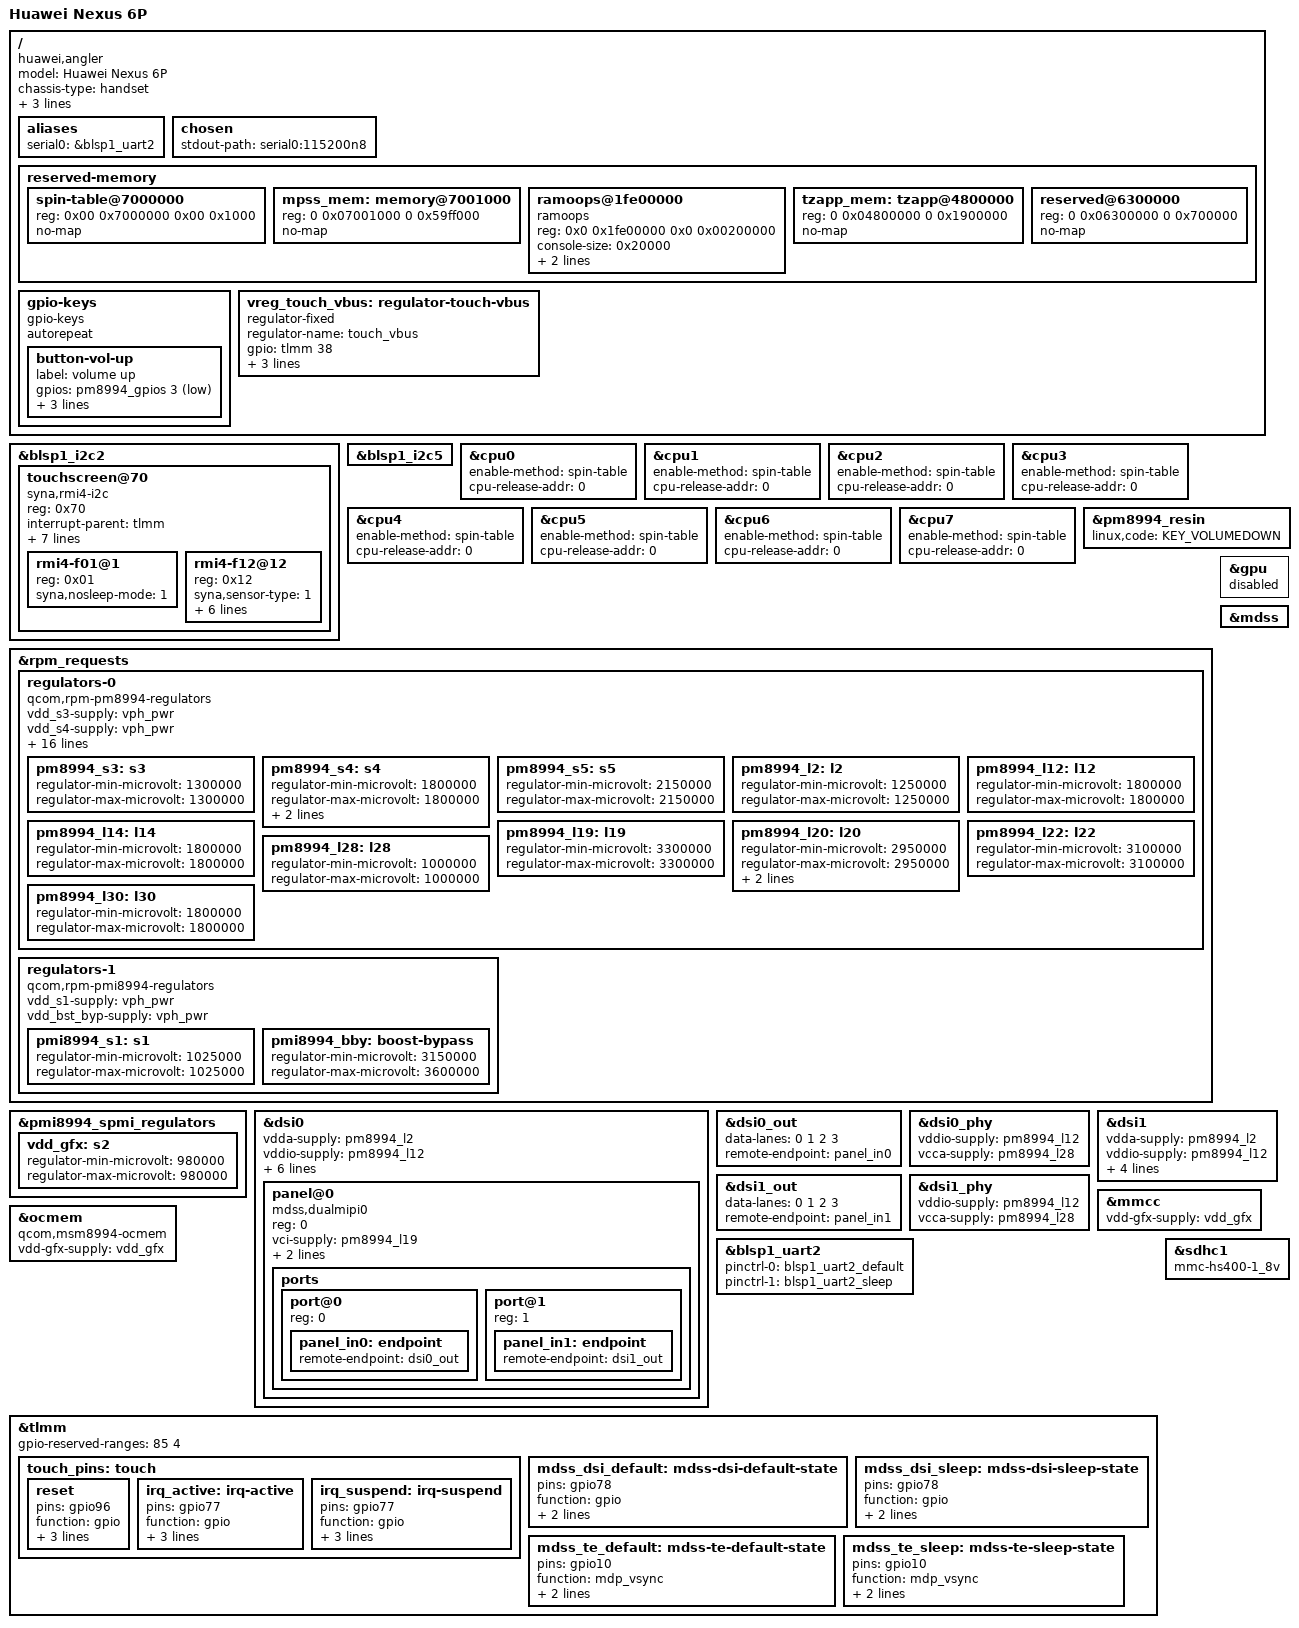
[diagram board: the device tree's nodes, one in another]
// SPDX-License-Identifier: GPL-2.0-only
/*
 * Copyright (c) 2015, Huawei Inc. All rights reserved.
 * Copyright (c) 2016, The Linux Foundation. All rights reserved.
 * Copyright (c) 2021-2024, Petr Vorel <petr.vorel@gmail.com>
 */

/dts-v1/;

#include "msm8994.dtsi"
#include "pm8994.dtsi"
#include "pmi8994.dtsi"
#include <dt-bindings/leds/common.h>

/* disabled downstream */
/delete-node/ &dfps_data_mem;

/* interferes with spin tables */
/delete-node/ &mpss_mem;

/* Framebuffer is somewhere else */
/delete-node/ &cont_splash_mem;

/ {
	model = "Huawei Nexus 6P";
	compatible = "huawei,angler", "qcom,msm8994";
	chassis-type = "handset";
	/* required for bootloader to select correct board */
	qcom,msm-id = <207 0x20000>;
	qcom,pmic-id = <0x10009 0x1000a 0x0 0x0>;
	qcom,board-id = <8026 0>;

	aliases {
		serial0 = &blsp1_uart2;
	};

	chosen {
		stdout-path = "serial0:115200n8";
	};

	reserved-memory {
		#address-cells = <2>;
		#size-cells = <2>;
		ranges;

		spin-table@7000000 {
			reg = <0x00 0x7000000 0x00 0x1000>;
			no-map;
		};

		mpss_mem: memory@7001000 {
			reg = <0 0x07001000 0 0x59ff000>;
			no-map;
		};
	
		ramoops@1fe00000 {
			compatible = "ramoops";
			reg = <0x0 0x1fe00000 0x0 0x00200000>;
			console-size = <0x20000>;
			pmsg-size = <0x20000>;
			record-size = <0x10000>;
		};

		tzapp_mem: tzapp@4800000 {
			reg = <0 0x04800000 0 0x1900000>;
			no-map;
		};

		reserved@6300000 {
			reg = <0 0x06300000 0 0x700000>;
			no-map;
		};
	};

	gpio-keys {
		compatible = "gpio-keys";
		autorepeat;

		button-vol-up {
			label = "volume up";
			gpios = <&pm8994_gpios 3 GPIO_ACTIVE_LOW>;
			linux,code = <KEY_VOLUMEUP>;
			wakeup-source;
			debounce-interval = <15>;
		};
	};

	vreg_touch_vbus: regulator-touch-vbus {
		compatible = "regulator-fixed";
		regulator-name = "touch_vbus";
		gpio = <&tlmm 38 GPIO_ACTIVE_HIGH>;
		enable-active-high;
		regulator-always-on;
		regulator-boot-on;
	};
};

&blsp1_i2c2 {
  status = "okay";

  touchscreen@70 {
    compatible = "syna,rmi4-i2c";
    reg = <0x70>;
    #address-cells = <1>;
    #size-cells = <0>;

    interrupt-parent = <&tlmm>;
    interrupts = <77 IRQ_TYPE_EDGE_FALLING>;

    vdd-supply = <&pm8994_l22>;
    vio-supply = <&pm8994_l30>;

    reset-gpios = <&tlmm 96 GPIO_ACTIVE_LOW>;

    syna,startup-delay-ms = <200>;

    pinctrl-names = "default", "sleep";
    pinctrl-0 = <&irq_active>;
    pinctrl-1 = <&irq_suspend>;

    rmi4-f01@1 {
      reg = <0x01>;
      syna,nosleep-mode = <1>;
    };

    rmi4-f12@12 {
      reg = <0x12>;
      syna,sensor-type = <1>;
      syna,clip-x-low = <0>;
      syna,clip-x-high = <1439>;
      syna,clip-y-low = <0>;
      syna,clip-y-high = <2559>;
      syna,x-flip = <1>;
      syna,y-flip = <1>;
    };
  };
};


&blsp1_i2c5 {
	status = "okay";

	/* SMB1351 charger */
};


&cpu0 {
	enable-method = "spin-table";
	cpu-release-addr = /bits/ 64 <0>;
};

&cpu1 {
	enable-method = "spin-table";
	cpu-release-addr = /bits/ 64 <0>;
};

&cpu2 {
	enable-method = "spin-table";
	cpu-release-addr = /bits/ 64 <0>;
};

&cpu3 {
	enable-method = "spin-table";
	cpu-release-addr = /bits/ 64 <0>;
};

&cpu4 {
	enable-method = "spin-table";
	cpu-release-addr = /bits/ 64 <0>;
};

&cpu5 {
	enable-method = "spin-table";
	cpu-release-addr = /bits/ 64 <0>;
};

&cpu6 {
	enable-method = "spin-table";
	cpu-release-addr = /bits/ 64 <0>;
};

&cpu7 {
	enable-method = "spin-table";
	cpu-release-addr = /bits/ 64 <0>;
};

&pm8994_resin {
	linux,code = <KEY_VOLUMEDOWN>;
	status = "okay";
};

&rpm_requests {
	regulators-0 {
		compatible = "qcom,rpm-pm8994-regulators";

		vdd_s3-supply = <&vph_pwr>;
		vdd_s4-supply = <&vph_pwr>;
		vdd_s5-supply = <&vph_pwr>;
		vdd_s7-supply = <&vph_pwr>;
		vdd_l1-supply = <&pmi8994_s1>;
		vdd_l2_26_28-supply = <&pm8994_s3>;
		vdd_l3_11-supply = <&pm8994_s3>;
		vdd_l4_27_31-supply = <&pm8994_s3>;
		vdd_l5_7-supply = <&pm8994_s5>;
		vdd_l6_12_32-supply = <&pm8994_s5>;
		vdd_l8_16_30-supply = <&vph_pwr>;
		vdd_l9_10_18_22-supply = <&pmi8994_bby>;
		vdd_l13_19_23_24-supply = <&pmi8994_bby>;
		vdd_l14_15-supply = <&pm8994_s5>;
		vdd_l17_29-supply = <&pmi8994_bby>;
		vdd_l20_21-supply = <&pmi8994_bby>;
		vdd_l25-supply = <&pm8994_s5>;
		vdd_lvs1_2-supply = <&pm8994_s4>;

		pm8994_s3: s3 {
			regulator-min-microvolt = <1300000>;
			regulator-max-microvolt = <1300000>;
		};

		/* sdhc1 vqmmc and bcm */
		pm8994_s4: s4 {
			regulator-min-microvolt = <1800000>;
			regulator-max-microvolt = <1800000>;
			regulator-system-load = <325000>;
			regulator-allow-set-load;
		};

		pm8994_s5: s5 {
			regulator-min-microvolt = <2150000>;
			regulator-max-microvolt = <2150000>;
		};

		pm8994_l2: l2 {
			regulator-min-microvolt = <1250000>;
			regulator-max-microvolt = <1250000>;
		};

		pm8994_l12: l12 {
			regulator-min-microvolt = <1800000>;
			regulator-max-microvolt = <1800000>;
		};

		pm8994_l14: l14 {
			regulator-min-microvolt = <1800000>;
			regulator-max-microvolt = <1800000>;
		};

		pm8994_l19: l19 {
			regulator-min-microvolt = <3300000>;
			regulator-max-microvolt = <3300000>;
		};

		/* sdhc1 vmmc */
		pm8994_l20: l20 {
			regulator-min-microvolt = <2950000>;
			regulator-max-microvolt = <2950000>;
			regulator-system-load = <570000>;
			regulator-allow-set-load;
		};

		/*Touchscreen */
		pm8994_l22: l22 {
			regulator-min-microvolt = <3100000>;
			regulator-max-microvolt = <3100000>;
		};

		pm8994_l28: l28 {
			regulator-min-microvolt = <1000000>;
			regulator-max-microvolt = <1000000>;
		};

		pm8994_l30: l30 {
			regulator-min-microvolt = <1800000>;
			regulator-max-microvolt = <1800000>;
		};
	};

	regulators-1 {
		compatible = "qcom,rpm-pmi8994-regulators";

		vdd_s1-supply = <&vph_pwr>;
		vdd_bst_byp-supply = <&vph_pwr>;

		pmi8994_s1: s1 {
			regulator-min-microvolt = <1025000>;
			regulator-max-microvolt = <1025000>;
		};

		/* S2 & S3 - VDD_GFX */

		pmi8994_bby: boost-bypass {
			regulator-min-microvolt = <3150000>;
			regulator-max-microvolt = <3600000>;
		};
	};
};

&pmi8994_spmi_regulators {
	vdd_gfx: s2 {
		regulator-min-microvolt = <980000>;
		regulator-max-microvolt = <980000>;
	};
};

&gpu {
	status = "disabled";
};

&mdss {
	status = "okay";
};

&dsi0 {
	status = "okay";
	#address-cells = <1>;
	#size-cells = <0>;

	vdda-supply = <&pm8994_l2>;
	vddio-supply = <&pm8994_l12>;
	vcca-supply = <&pm8994_l28>;
	vdd-supply = <&pm8994_l14>;

	pinctrl-names = "default", "sleep";
	pinctrl-0 = <&mdss_dsi_default &mdss_te_default>;
	pinctrl-1 = <&mdss_dsi_sleep &mdss_te_sleep>;

	qcom,dual-dsi-mode;
	qcom,master-dsi;

	panel@0 {
		compatible = "mdss,dualmipi0";
		reg = <0>;

		vci-supply = <&pm8994_l19>;
		reset-gpios = <&tlmm 78 GPIO_ACTIVE_LOW>;

		/* keep the bootloader's panel state, only probe it */
		samsung,inherit-splash;

		ports {
			#address-cells = <1>;
			#size-cells = <0>;

			port@0 {
				reg = <0>;

				panel_in0: endpoint {
					remote-endpoint = <&dsi0_out>;
				};
			};

			port@1 {
				reg = <1>;

				panel_in1: endpoint {
					remote-endpoint = <&dsi1_out>;
				};
			};
		};
	};
};

&dsi0_out {
	data-lanes = <0 1 2 3>;
	remote-endpoint = <&panel_in0>;
};

&dsi0_phy {
	status = "okay";

	vddio-supply = <&pm8994_l12>;
	vcca-supply = <&pm8994_l28>;

};

&dsi1 {
	status = "okay";

	vdda-supply = <&pm8994_l2>;
	vddio-supply = <&pm8994_l12>;
	vcca-supply = <&pm8994_l28>;
	vdd-supply = <&pm8994_l14>;

	qcom,dual-dsi-mode;

	/* PLL0 drives both DSI link clocks in bonded (dual) DSI mode */
	assigned-clock-parents = <&dsi0_phy 0>, <&dsi0_phy 1>;
};

&dsi1_out {
	data-lanes = <0 1 2 3>;
	remote-endpoint = <&panel_in1>;
};

&dsi1_phy {
	status = "okay";

	vddio-supply = <&pm8994_l12>;
	vcca-supply = <&pm8994_l28>;
};

&mmcc {
	vdd-gfx-supply = <&vdd_gfx>;
};


&ocmem {
	compatible = "qcom,msm8994-ocmem";
	vdd-gfx-supply = <&vdd_gfx>;
};

&blsp1_uart2 {
	status = "okay";
	pinctrl-names = "default", "sleep";
	pinctrl-0 = <&blsp1_uart2_default>;
	pinctrl-1 = <&blsp1_uart2_sleep>;
};

&tlmm {
	gpio-reserved-ranges = <85 4>;

	touch_pins: touch {
		reset: reset {
			pins = "gpio96";
			function = "gpio";
			drive-strength = <8>;
			bias-disable;
			output-high;
		};

		irq_active: irq-active {
			pins = "gpio77";
			function = "gpio";
			drive-strength = <8>;
			bias-pull-up;
			input-enable;
		};

		irq_suspend: irq-suspend {
			pins = "gpio77";
			function = "gpio";
			drive-strength = <2>;
			bias-disable;
			input-enable;
		};
	};

	mdss_dsi_default: mdss-dsi-default-state {
		pins = "gpio78";
		function = "gpio";
		drive-strength = <8>;
		bias-disable;
	};

	mdss_dsi_sleep: mdss-dsi-sleep-state {
		pins = "gpio78";
		function = "gpio";
		drive-strength = <2>;
		bias-pull-down;
	};

	mdss_te_default: mdss-te-default-state {
		pins = "gpio10";
		function = "mdp_vsync";
		drive-strength = <2>;
		bias-pull-down;
	};

	mdss_te_sleep: mdss-te-sleep-state {
		pins = "gpio10";
		function = "mdp_vsync";
		drive-strength = <2>;
		bias-pull-down;
	};

};


&sdhc1 {
	status = "okay";
	mmc-hs400-1_8v;
};
